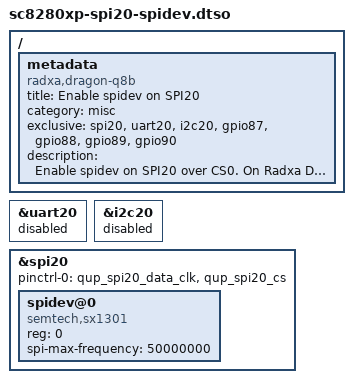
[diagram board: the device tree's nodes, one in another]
// SPDX-License-Identifier: BSD-3-Clause
/*
 * Copyright (c) 2026 Radxa Computer (Shenzhen) Co., Ltd.
 */

/dts-v1/;
/plugin/;

/ {
	metadata {
		title = "Enable spidev on SPI20";
		compatible = "radxa,dragon-q8b";
		category = "misc";
		exclusive = "spi20", "uart20", "i2c20", "gpio87", "gpio88", "gpio89", "gpio90";
		description = "Enable spidev on SPI20 over CS0.
On Radxa Dragon Q8B, this is pin 21(miso), 19(mosi), 23(sclk), 24(cs0).";
	};
};

&uart20 {
	status = "disabled";
};

&i2c20 {
	status = "disabled";
};

&spi20 {
	pinctrl-0 = <&qup_spi20_data_clk>, <&qup_spi20_cs>;
	pinctrl-names = "default";
	
	status = "okay";
	
	spidev@0 {
		compatible = "semtech,sx1301";
		status = "okay";
		reg = <0>;
		spi-max-frequency = <50000000>;
	};
};
